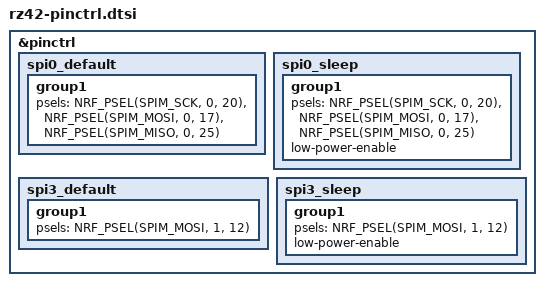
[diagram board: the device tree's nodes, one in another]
/*
 * Copyright (c) 2024 The ZMK Contributors
 * SPDX-License-Identifier: MIT
 */

&pinctrl {
  /* spi0 for nice!view comaptible display */
  spi0_default: spi0_default {
    group1 {
      psels
        = <NRF_PSEL(SPIM_SCK, 0, 20)>
        , <NRF_PSEL(SPIM_MOSI, 0, 17)>
        , <NRF_PSEL(SPIM_MISO, 0, 25)>
        ;
    };
  };

  spi0_sleep: spi0_sleep {
    group1 {
      psels
        = <NRF_PSEL(SPIM_SCK, 0, 20)>
        , <NRF_PSEL(SPIM_MOSI, 0, 17)>
        , <NRF_PSEL(SPIM_MISO, 0, 25)>
        ;
      low-power-enable;
    };
  };

  /* spi3 for led strip */
  spi3_default: spi3_default {
    group1 {
      psels
        = <NRF_PSEL(SPIM_MOSI, 1, 12)>
        ;
    };
  };

  spi3_sleep: spi3_sleep {
    group1 {
      psels
        = <NRF_PSEL(SPIM_MOSI, 1, 12)>
        ;
      low-power-enable;
    };
  };
};
